VERSION "1.0"

BU_: ECM ABS BCM CLUSTER

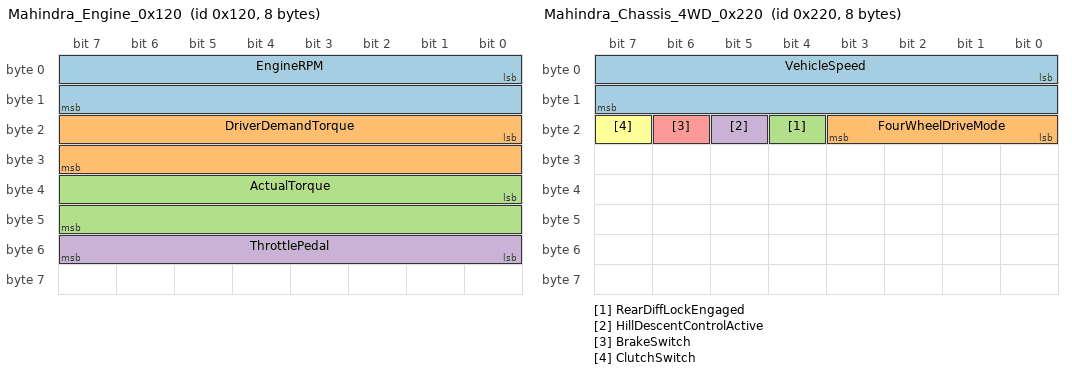
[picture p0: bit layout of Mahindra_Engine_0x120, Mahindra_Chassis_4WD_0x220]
BO_ 288 Mahindra_Engine_0x120: 8 ECM
 SG_ EngineRPM : 0|16@1+ (0.25,0) [0|6000] "rpm" CLUSTER,ABS
 SG_ DriverDemandTorque : 16|16@1+ (0.1,-500) [-500|600] "Nm" ABS
 SG_ ActualTorque : 32|16@1+ (0.1,-500) [-500|600] "Nm" ABS
 SG_ ThrottlePedal : 48|8@1+ (0.392157,0) [0|100] "%" CLUSTER

BO_ 544 Mahindra_Chassis_4WD_0x220: 8 ABS
 SG_ VehicleSpeed : 0|16@1+ (0.01,0) [0|250] "km/h" ECM,CLUSTER
 SG_ FourWheelDriveMode : 16|4@1+ (1,0) [0|3] "" CLUSTER
 SG_ RearDiffLockEngaged : 20|1@1+ (1,0) [0|1] "" CLUSTER
 SG_ HillDescentControlActive : 21|1@1+ (1,0) [0|1] "" CLUSTER
 SG_ BrakeSwitch : 22|1@1+ (1,0) [0|1] "" ECM
 SG_ ClutchSwitch : 23|1@1+ (1,0) [0|1] "" ECM

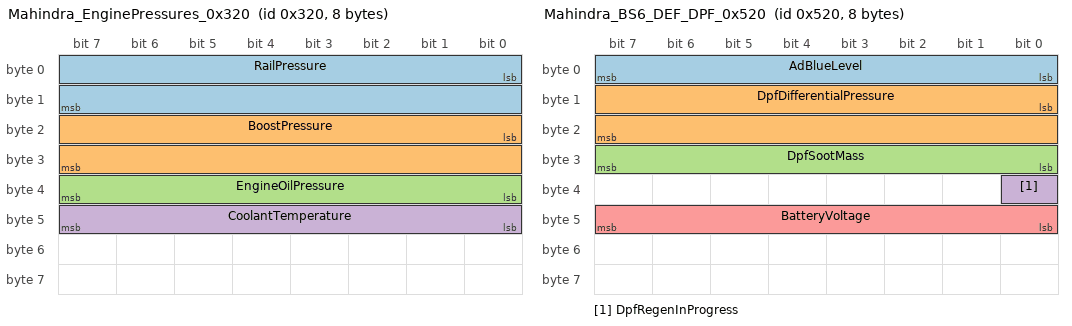
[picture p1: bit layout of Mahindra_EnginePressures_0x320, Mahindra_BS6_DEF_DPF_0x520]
BO_ 800 Mahindra_EnginePressures_0x320: 8 ECM
 SG_ RailPressure : 0|16@1+ (0.1,0) [0|2500] "bar" CLUSTER
 SG_ BoostPressure : 16|16@1+ (0.1,0) [0|400] "kPa" CLUSTER
 SG_ EngineOilPressure : 32|8@1+ (0.05,0) [0|10] "bar" CLUSTER
 SG_ CoolantTemperature : 40|8@1+ (1,-40) [-40|150] "degC" CLUSTER

BO_ 1312 Mahindra_BS6_DEF_DPF_0x520: 8 ECM
 SG_ AdBlueLevel : 0|8@1+ (0.392157,0) [0|100] "%" CLUSTER
 SG_ DpfDifferentialPressure : 8|16@1+ (0.1,0) [0|800] "mbar" CLUSTER
 SG_ DpfSootMass : 24|8@1+ (0.2,0) [0|50] "g" CLUSTER
 SG_ DpfRegenInProgress : 32|1@1+ (1,0) [0|1] "" CLUSTER
 SG_ BatteryVoltage : 40|8@1+ (0.1,0) [0|25] "V" CLUSTER

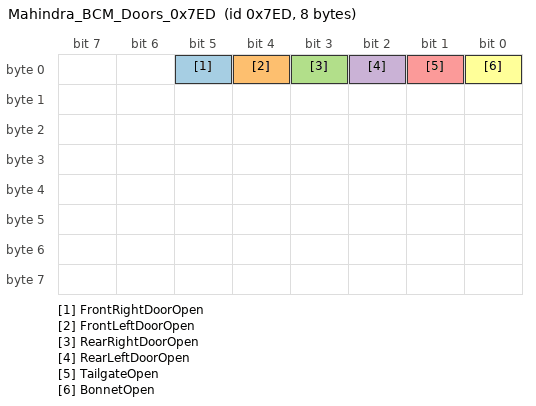
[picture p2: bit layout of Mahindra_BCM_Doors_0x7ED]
BO_ 2029 Mahindra_BCM_Doors_0x7ED: 8 BCM
 SG_ FrontRightDoorOpen : 5|1@1+ (1,0) [0|1] "" CLUSTER
 SG_ FrontLeftDoorOpen : 4|1@1+ (1,0) [0|1] "" CLUSTER
 SG_ RearRightDoorOpen : 3|1@1+ (1,0) [0|1] "" CLUSTER
 SG_ RearLeftDoorOpen : 2|1@1+ (1,0) [0|1] "" CLUSTER
 SG_ TailgateOpen : 1|1@1+ (1,0) [0|1] "" CLUSTER
 SG_ BonnetOpen : 0|1@1+ (1,0) [0|1] "" CLUSTER
